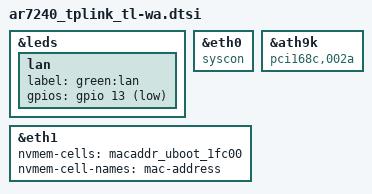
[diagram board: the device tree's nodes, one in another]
// SPDX-License-Identifier: GPL-2.0-or-later OR MIT

#include "ar7240_tplink.dtsi"

&leds {
	lan {
		label = "green:lan";
		gpios = <&gpio 13 GPIO_ACTIVE_LOW>;
	};
};

&eth0 {
	compatible = "syscon", "simple-mfd";
};

&eth1 {
	nvmem-cells = <&macaddr_uboot_1fc00>;
	nvmem-cell-names = "mac-address";
};

&ath9k {
	compatible = "pci168c,002a";
};
